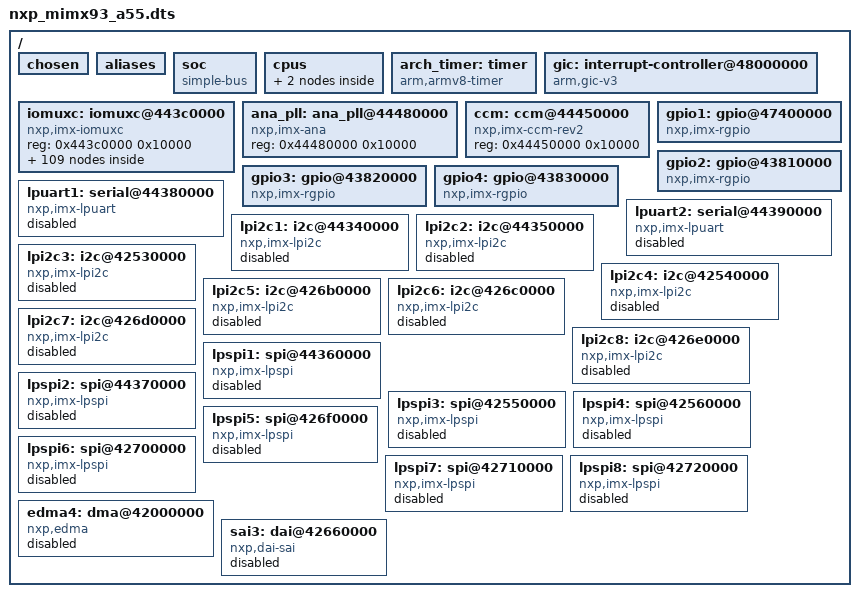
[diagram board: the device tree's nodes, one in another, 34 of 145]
/dts-v1/;

/ {
	#address-cells = < 0x1 >;
	#size-cells = < 0x1 >;
	chosen {
	};
	aliases {
	};
	soc {
		#address-cells = < 0x1 >;
		#size-cells = < 0x1 >;
		compatible = "simple-bus";
		ranges;
	};
	cpus {
		#address-cells = < 0x1 >;
		#size-cells = < 0x0 >;
		cpu@0 {
			device_type = "cpu";
			compatible = "arm,cortex-a55";
			reg = < 0x0 >;
		};
		cpu@100 {
			device_type = "cpu";
			compatible = "arm,cortex-a55";
			reg = < 0x100 >;
		};
	};
	arch_timer: timer {
		compatible = "arm,armv8-timer";
		interrupts = < 0x1 0xd 0x2 0xa0 >, < 0x1 0xe 0x2 0xa0 >, < 0x1 0xb 0x2 0xa0 >, < 0x1 0xa 0x2 0xa0 >;
		interrupt-parent = < &gic >;
	};
	gic: interrupt-controller@48000000 {
		compatible = "arm,gic-v3", "arm,gic";
		reg = < 0x48000000 0x10000 >, < 0x48040000 0xc0000 >;
		interrupt-controller;
		#interrupt-cells = < 0x4 >;
		status = "okay";
		phandle = < 0x1 >;
	};
	iomuxc: iomuxc@443c0000 {
		compatible = "nxp,imx-iomuxc";
		reg = < 0x443c0000 0x10000 >;
		status = "okay";
		pinctrl: pinctrl {
			status = "okay";
			compatible = "nxp,imx93-pinctrl";
		};
		iomuxc1_ccm_clko1_gpio_io_gpio3_io26: IOMUXC1_CCM_CLKO1_GPIO_IO_GPIO3_IO26 {
			pinmux = < 0x443c0088 0x5 0x0 0x0 0x443c0238 >;
			phandle = < 0x4a >;
		};
		iomuxc1_ccm_clko2_gpio_io_gpio3_io27: IOMUXC1_CCM_CLKO2_GPIO_IO_GPIO3_IO27 {
			pinmux = < 0x443c008c 0x5 0x0 0x0 0x443c023c >;
			phandle = < 0x4b >;
		};
		iomuxc1_ccm_clko3_gpio_io_gpio4_io28: IOMUXC1_CCM_CLKO3_GPIO_IO_GPIO4_IO28 {
			pinmux = < 0x443c0090 0x5 0x0 0x0 0x443c0240 >;
			phandle = < 0x6c >;
		};
		iomuxc1_ccm_clko4_gpio_io_gpio4_io29: IOMUXC1_CCM_CLKO4_GPIO_IO_GPIO4_IO29 {
			pinmux = < 0x443c0094 0x5 0x0 0x0 0x443c0244 >;
			phandle = < 0x6d >;
		};
		iomuxc1_dap_tclk_swclk_gpio_io_gpio3_io30: IOMUXC1_DAP_TCLK_SWCLK_GPIO_IO_GPIO3_IO30 {
			pinmux = < 0x443c0008 0x5 0x0 0x0 0x443c01b8 >;
			phandle = < 0x4e >;
		};
		iomuxc1_dap_tdi_gpio_io_gpio3_io28: IOMUXC1_DAP_TDI_GPIO_IO_GPIO3_IO28 {
			pinmux = < 0x443c0000 0x5 0x0 0x0 0x443c01b0 >;
			phandle = < 0x4c >;
		};
		iomuxc1_dap_tdo_traceswo_gpio_io_gpio3_io31: IOMUXC1_DAP_TDO_TRACESWO_GPIO_IO_GPIO3_IO31 {
			pinmux = < 0x443c000c 0x5 0x0 0x0 0x443c01bc >;
			phandle = < 0x4f >;
		};
		iomuxc1_dap_tms_swdio_gpio_io_gpio3_io29: IOMUXC1_DAP_TMS_SWDIO_GPIO_IO_GPIO3_IO29 {
			pinmux = < 0x443c0004 0x5 0x0 0x0 0x443c01b4 >;
			phandle = < 0x4d >;
		};
		iomuxc1_enet1_mdc_gpio_io_gpio4_io00: IOMUXC1_ENET1_MDC_GPIO_IO_GPIO4_IO00 {
			pinmux = < 0x443c0098 0x5 0x0 0x0 0x443c0248 >;
			phandle = < 0x50 >;
		};
		iomuxc1_enet1_mdio_gpio_io_gpio4_io01: IOMUXC1_ENET1_MDIO_GPIO_IO_GPIO4_IO01 {
			pinmux = < 0x443c009c 0x5 0x0 0x0 0x443c024c >;
			phandle = < 0x51 >;
		};
		iomuxc1_enet1_rd0_gpio_io_gpio4_io10: IOMUXC1_ENET1_RD0_GPIO_IO_GPIO4_IO10 {
			pinmux = < 0x443c00c0 0x5 0x0 0x0 0x443c0270 >;
			phandle = < 0x5a >;
		};
		iomuxc1_enet1_rd1_gpio_io_gpio4_io11: IOMUXC1_ENET1_RD1_GPIO_IO_GPIO4_IO11 {
			pinmux = < 0x443c00c4 0x5 0x0 0x0 0x443c0274 >;
			phandle = < 0x5b >;
		};
		iomuxc1_enet1_rd2_gpio_io_gpio4_io12: IOMUXC1_ENET1_RD2_GPIO_IO_GPIO4_IO12 {
			pinmux = < 0x443c00c8 0x5 0x0 0x0 0x443c0278 >;
			phandle = < 0x5c >;
		};
		iomuxc1_enet1_rd3_gpio_io_gpio4_io13: IOMUXC1_ENET1_RD3_GPIO_IO_GPIO4_IO13 {
			pinmux = < 0x443c00cc 0x5 0x0 0x0 0x443c027c >;
			phandle = < 0x5d >;
		};
		iomuxc1_enet1_rxc_gpio_io_gpio4_io09: IOMUXC1_ENET1_RXC_GPIO_IO_GPIO4_IO09 {
			pinmux = < 0x443c00bc 0x5 0x0 0x0 0x443c026c >;
			phandle = < 0x59 >;
		};
		iomuxc1_enet1_rx_ctl_gpio_io_gpio4_io08: IOMUXC1_ENET1_RX_CTL_GPIO_IO_GPIO4_IO08 {
			pinmux = < 0x443c00b8 0x5 0x0 0x0 0x443c0268 >;
			phandle = < 0x58 >;
		};
		iomuxc1_enet1_td0_gpio_io_gpio4_io05: IOMUXC1_ENET1_TD0_GPIO_IO_GPIO4_IO05 {
			pinmux = < 0x443c00ac 0x5 0x0 0x0 0x443c025c >;
			phandle = < 0x55 >;
		};
		iomuxc1_enet1_td1_gpio_io_gpio4_io04: IOMUXC1_ENET1_TD1_GPIO_IO_GPIO4_IO04 {
			pinmux = < 0x443c00a8 0x5 0x0 0x0 0x443c0258 >;
			phandle = < 0x54 >;
		};
		iomuxc1_enet1_td2_gpio_io_gpio4_io03: IOMUXC1_ENET1_TD2_GPIO_IO_GPIO4_IO03 {
			pinmux = < 0x443c00a4 0x5 0x0 0x0 0x443c0254 >;
			phandle = < 0x53 >;
		};
		iomuxc1_enet1_td3_gpio_io_gpio4_io02: IOMUXC1_ENET1_TD3_GPIO_IO_GPIO4_IO02 {
			pinmux = < 0x443c00a0 0x5 0x0 0x0 0x443c0250 >;
			phandle = < 0x52 >;
		};
		iomuxc1_enet1_txc_gpio_io_gpio4_io07: IOMUXC1_ENET1_TXC_GPIO_IO_GPIO4_IO07 {
			pinmux = < 0x443c00b4 0x5 0x0 0x0 0x443c0264 >;
			phandle = < 0x57 >;
		};
		iomuxc1_enet1_tx_ctl_gpio_io_gpio4_io06: IOMUXC1_ENET1_TX_CTL_GPIO_IO_GPIO4_IO06 {
			pinmux = < 0x443c00b0 0x5 0x0 0x0 0x443c0260 >;
			phandle = < 0x56 >;
		};
		iomuxc1_enet2_mdc_gpio_io_gpio4_io14: IOMUXC1_ENET2_MDC_GPIO_IO_GPIO4_IO14 {
			pinmux = < 0x443c00d0 0x5 0x0 0x0 0x443c0280 >;
			phandle = < 0x5e >;
		};
		iomuxc1_enet2_mdio_gpio_io_gpio4_io15: IOMUXC1_ENET2_MDIO_GPIO_IO_GPIO4_IO15 {
			pinmux = < 0x443c00d4 0x5 0x0 0x0 0x443c0284 >;
			phandle = < 0x5f >;
		};
		iomuxc1_enet2_rd0_gpio_io_gpio4_io24: IOMUXC1_ENET2_RD0_GPIO_IO_GPIO4_IO24 {
			pinmux = < 0x443c00f8 0x5 0x0 0x0 0x443c02a8 >;
			phandle = < 0x68 >;
		};
		iomuxc1_enet2_rd1_gpio_io_gpio4_io25: IOMUXC1_ENET2_RD1_GPIO_IO_GPIO4_IO25 {
			pinmux = < 0x443c00fc 0x5 0x0 0x0 0x443c02ac >;
			phandle = < 0x69 >;
		};
		iomuxc1_enet2_rd2_gpio_io_gpio4_io26: IOMUXC1_ENET2_RD2_GPIO_IO_GPIO4_IO26 {
			pinmux = < 0x443c0100 0x5 0x0 0x0 0x443c02b0 >;
			phandle = < 0x6a >;
		};
		iomuxc1_enet2_rd3_gpio_io_gpio4_io27: IOMUXC1_ENET2_RD3_GPIO_IO_GPIO4_IO27 {
			pinmux = < 0x443c0104 0x5 0x0 0x0 0x443c02b4 >;
			phandle = < 0x6b >;
		};
		iomuxc1_enet2_rxc_gpio_io_gpio4_io23: IOMUXC1_ENET2_RXC_GPIO_IO_GPIO4_IO23 {
			pinmux = < 0x443c00f4 0x5 0x0 0x0 0x443c02a4 >;
			phandle = < 0x67 >;
		};
		iomuxc1_enet2_rx_ctl_gpio_io_gpio4_io22: IOMUXC1_ENET2_RX_CTL_GPIO_IO_GPIO4_IO22 {
			pinmux = < 0x443c00f0 0x5 0x0 0x0 0x443c02a0 >;
			phandle = < 0x66 >;
		};
		iomuxc1_enet2_td0_gpio_io_gpio4_io19: IOMUXC1_ENET2_TD0_GPIO_IO_GPIO4_IO19 {
			pinmux = < 0x443c00e4 0x5 0x0 0x0 0x443c0294 >;
			phandle = < 0x63 >;
		};
		iomuxc1_enet2_td1_gpio_io_gpio4_io18: IOMUXC1_ENET2_TD1_GPIO_IO_GPIO4_IO18 {
			pinmux = < 0x443c00e0 0x5 0x0 0x0 0x443c0290 >;
			phandle = < 0x62 >;
		};
		iomuxc1_enet2_td2_gpio_io_gpio4_io17: IOMUXC1_ENET2_TD2_GPIO_IO_GPIO4_IO17 {
			pinmux = < 0x443c00dc 0x5 0x0 0x0 0x443c028c >;
			phandle = < 0x61 >;
		};
		iomuxc1_enet2_td3_gpio_io_gpio4_io16: IOMUXC1_ENET2_TD3_GPIO_IO_GPIO4_IO16 {
			pinmux = < 0x443c00d8 0x5 0x0 0x0 0x443c0288 >;
			phandle = < 0x60 >;
		};
		iomuxc1_enet2_txc_gpio_io_gpio4_io21: IOMUXC1_ENET2_TXC_GPIO_IO_GPIO4_IO21 {
			pinmux = < 0x443c00ec 0x5 0x0 0x0 0x443c029c >;
			phandle = < 0x65 >;
		};
		iomuxc1_enet2_tx_ctl_gpio_io_gpio4_io20: IOMUXC1_ENET2_TX_CTL_GPIO_IO_GPIO4_IO20 {
			pinmux = < 0x443c00e8 0x5 0x0 0x0 0x443c0298 >;
			phandle = < 0x64 >;
		};
		iomuxc1_gpio_io00_gpio_io_gpio2_io00: IOMUXC1_GPIO_IO00_GPIO_IO_GPIO2_IO00 {
			pinmux = < 0x443c0010 0x0 0x0 0x0 0x443c01c0 >;
			phandle = < 0x12 >;
		};
		iomuxc1_gpio_io01_gpio_io_gpio2_io01: IOMUXC1_GPIO_IO01_GPIO_IO_GPIO2_IO01 {
			pinmux = < 0x443c0014 0x0 0x0 0x0 0x443c01c4 >;
			phandle = < 0x13 >;
		};
		iomuxc1_gpio_io02_gpio_io_gpio2_io02: IOMUXC1_GPIO_IO02_GPIO_IO_GPIO2_IO02 {
			pinmux = < 0x443c0018 0x0 0x0 0x0 0x443c01c8 >;
			phandle = < 0x14 >;
		};
		iomuxc1_gpio_io03_gpio_io_gpio2_io03: IOMUXC1_GPIO_IO03_GPIO_IO_GPIO2_IO03 {
			pinmux = < 0x443c001c 0x0 0x0 0x0 0x443c01cc >;
			phandle = < 0x15 >;
		};
		iomuxc1_gpio_io04_gpio_io_gpio2_io04: IOMUXC1_GPIO_IO04_GPIO_IO_GPIO2_IO04 {
			pinmux = < 0x443c0020 0x0 0x0 0x0 0x443c01d0 >;
			phandle = < 0x16 >;
		};
		iomuxc1_gpio_io05_gpio_io_gpio2_io05: IOMUXC1_GPIO_IO05_GPIO_IO_GPIO2_IO05 {
			pinmux = < 0x443c0024 0x0 0x0 0x0 0x443c01d4 >;
			phandle = < 0x17 >;
		};
		iomuxc1_gpio_io06_gpio_io_gpio2_io06: IOMUXC1_GPIO_IO06_GPIO_IO_GPIO2_IO06 {
			pinmux = < 0x443c0028 0x0 0x0 0x0 0x443c01d8 >;
			phandle = < 0x18 >;
		};
		iomuxc1_gpio_io07_gpio_io_gpio2_io07: IOMUXC1_GPIO_IO07_GPIO_IO_GPIO2_IO07 {
			pinmux = < 0x443c002c 0x0 0x0 0x0 0x443c01dc >;
			phandle = < 0x19 >;
		};
		iomuxc1_gpio_io08_gpio_io_gpio2_io08: IOMUXC1_GPIO_IO08_GPIO_IO_GPIO2_IO08 {
			pinmux = < 0x443c0030 0x0 0x0 0x0 0x443c01e0 >;
			phandle = < 0x1a >;
		};
		iomuxc1_gpio_io09_gpio_io_gpio2_io09: IOMUXC1_GPIO_IO09_GPIO_IO_GPIO2_IO09 {
			pinmux = < 0x443c0034 0x0 0x0 0x0 0x443c01e4 >;
			phandle = < 0x1b >;
		};
		iomuxc1_gpio_io10_gpio_io_gpio2_io10: IOMUXC1_GPIO_IO10_GPIO_IO_GPIO2_IO10 {
			pinmux = < 0x443c0038 0x0 0x0 0x0 0x443c01e8 >;
			phandle = < 0x1c >;
		};
		iomuxc1_gpio_io11_gpio_io_gpio2_io11: IOMUXC1_GPIO_IO11_GPIO_IO_GPIO2_IO11 {
			pinmux = < 0x443c003c 0x0 0x0 0x0 0x443c01ec >;
			phandle = < 0x1d >;
		};
		iomuxc1_gpio_io12_gpio_io_gpio2_io12: IOMUXC1_GPIO_IO12_GPIO_IO_GPIO2_IO12 {
			pinmux = < 0x443c0040 0x0 0x0 0x0 0x443c01f0 >;
			phandle = < 0x1e >;
		};
		iomuxc1_gpio_io13_gpio_io_gpio2_io13: IOMUXC1_GPIO_IO13_GPIO_IO_GPIO2_IO13 {
			pinmux = < 0x443c0044 0x0 0x0 0x0 0x443c01f4 >;
			phandle = < 0x1f >;
		};
		iomuxc1_gpio_io14_gpio_io_gpio2_io14: IOMUXC1_GPIO_IO14_GPIO_IO_GPIO2_IO14 {
			pinmux = < 0x443c0048 0x0 0x0 0x0 0x443c01f8 >;
			phandle = < 0x20 >;
		};
		iomuxc1_gpio_io15_gpio_io_gpio2_io15: IOMUXC1_GPIO_IO15_GPIO_IO_GPIO2_IO15 {
			pinmux = < 0x443c004c 0x0 0x0 0x0 0x443c01fc >;
			phandle = < 0x21 >;
		};
		iomuxc1_gpio_io16_gpio_io_gpio2_io16: IOMUXC1_GPIO_IO16_GPIO_IO_GPIO2_IO16 {
			pinmux = < 0x443c0050 0x0 0x0 0x0 0x443c0200 >;
			phandle = < 0x22 >;
		};
		iomuxc1_gpio_io17_gpio_io_gpio2_io17: IOMUXC1_GPIO_IO17_GPIO_IO_GPIO2_IO17 {
			pinmux = < 0x443c0054 0x0 0x0 0x0 0x443c0204 >;
			phandle = < 0x23 >;
		};
		iomuxc1_gpio_io18_gpio_io_gpio2_io18: IOMUXC1_GPIO_IO18_GPIO_IO_GPIO2_IO18 {
			pinmux = < 0x443c0058 0x0 0x0 0x0 0x443c0208 >;
			phandle = < 0x24 >;
		};
		iomuxc1_gpio_io19_gpio_io_gpio2_io19: IOMUXC1_GPIO_IO19_GPIO_IO_GPIO2_IO19 {
			pinmux = < 0x443c005c 0x0 0x0 0x0 0x443c020c >;
			phandle = < 0x25 >;
		};
		iomuxc1_gpio_io20_gpio_io_gpio2_io20: IOMUXC1_GPIO_IO20_GPIO_IO_GPIO2_IO20 {
			pinmux = < 0x443c0060 0x0 0x0 0x0 0x443c0210 >;
			phandle = < 0x26 >;
		};
		iomuxc1_gpio_io21_gpio_io_gpio2_io21: IOMUXC1_GPIO_IO21_GPIO_IO_GPIO2_IO21 {
			pinmux = < 0x443c0064 0x0 0x0 0x0 0x443c0214 >;
			phandle = < 0x27 >;
		};
		iomuxc1_gpio_io22_gpio_io_gpio2_io22: IOMUXC1_GPIO_IO22_GPIO_IO_GPIO2_IO22 {
			pinmux = < 0x443c0068 0x0 0x0 0x0 0x443c0218 >;
			phandle = < 0x28 >;
		};
		iomuxc1_gpio_io23_gpio_io_gpio2_io23: IOMUXC1_GPIO_IO23_GPIO_IO_GPIO2_IO23 {
			pinmux = < 0x443c006c 0x0 0x0 0x0 0x443c021c >;
			phandle = < 0x29 >;
		};
		iomuxc1_gpio_io24_gpio_io_gpio2_io24: IOMUXC1_GPIO_IO24_GPIO_IO_GPIO2_IO24 {
			pinmux = < 0x443c0070 0x0 0x0 0x0 0x443c0220 >;
			phandle = < 0x2a >;
		};
		iomuxc1_gpio_io25_gpio_io_gpio2_io25: IOMUXC1_GPIO_IO25_GPIO_IO_GPIO2_IO25 {
			pinmux = < 0x443c0074 0x0 0x0 0x0 0x443c0224 >;
			phandle = < 0x2b >;
		};
		iomuxc1_gpio_io26_gpio_io_gpio2_io26: IOMUXC1_GPIO_IO26_GPIO_IO_GPIO2_IO26 {
			pinmux = < 0x443c0078 0x0 0x0 0x0 0x443c0228 >;
			phandle = < 0x2c >;
		};
		iomuxc1_gpio_io27_gpio_io_gpio2_io27: IOMUXC1_GPIO_IO27_GPIO_IO_GPIO2_IO27 {
			pinmux = < 0x443c007c 0x0 0x0 0x0 0x443c022c >;
			phandle = < 0x2d >;
		};
		iomuxc1_gpio_io28_gpio_io_gpio2_io28: IOMUXC1_GPIO_IO28_GPIO_IO_GPIO2_IO28 {
			pinmux = < 0x443c0080 0x0 0x0 0x0 0x443c0230 >;
			phandle = < 0x2e >;
		};
		iomuxc1_gpio_io29_gpio_io_gpio2_io29: IOMUXC1_GPIO_IO29_GPIO_IO_GPIO2_IO29 {
			pinmux = < 0x443c0084 0x0 0x0 0x0 0x443c0234 >;
			phandle = < 0x2f >;
		};
		iomuxc1_i2c1_scl_gpio_io_gpio1_io00: IOMUXC1_I2C1_SCL_GPIO_IO_GPIO1_IO00 {
			pinmux = < 0x443c0170 0x5 0x0 0x0 0x443c0320 >;
			phandle = < 0x2 >;
		};
		iomuxc1_i2c1_sda_gpio_io_gpio1_io01: IOMUXC1_I2C1_SDA_GPIO_IO_GPIO1_IO01 {
			pinmux = < 0x443c0174 0x5 0x0 0x0 0x443c0324 >;
			phandle = < 0x3 >;
		};
		iomuxc1_i2c2_scl_gpio_io_gpio1_io02: IOMUXC1_I2C2_SCL_GPIO_IO_GPIO1_IO02 {
			pinmux = < 0x443c0178 0x5 0x0 0x0 0x443c0328 >;
			phandle = < 0x4 >;
		};
		iomuxc1_i2c2_sda_gpio_io_gpio1_io03: IOMUXC1_I2C2_SDA_GPIO_IO_GPIO1_IO03 {
			pinmux = < 0x443c017c 0x5 0x0 0x0 0x443c032c >;
			phandle = < 0x5 >;
		};
		iomuxc1_pdm_bit_stream0_gpio_io_gpio1_io09: IOMUXC1_PDM_BIT_STREAM0_GPIO_IO_GPIO1_IO09 {
			pinmux = < 0x443c0194 0x5 0x0 0x0 0x443c0344 >;
			phandle = < 0xb >;
		};
		iomuxc1_pdm_bit_stream1_gpio_io_gpio1_io10: IOMUXC1_PDM_BIT_STREAM1_GPIO_IO_GPIO1_IO10 {
			pinmux = < 0x443c0198 0x5 0x0 0x0 0x443c0348 >;
			phandle = < 0xc >;
		};
		iomuxc1_pdm_clk_gpio_io_gpio1_io08: IOMUXC1_PDM_CLK_GPIO_IO_GPIO1_IO08 {
			pinmux = < 0x443c0190 0x5 0x0 0x0 0x443c0340 >;
			phandle = < 0xa >;
		};
		iomuxc1_sai1_rxd0_gpio_io_gpio1_io14: IOMUXC1_SAI1_RXD0_GPIO_IO_GPIO1_IO14 {
			pinmux = < 0x443c01a8 0x5 0x0 0x0 0x443c0358 >;
			phandle = < 0x10 >;
		};
		iomuxc1_sai1_txc_gpio_io_gpio1_io12: IOMUXC1_SAI1_TXC_GPIO_IO_GPIO1_IO12 {
			pinmux = < 0x443c01a0 0x5 0x0 0x0 0x443c0350 >;
			phandle = < 0xe >;
		};
		iomuxc1_sai1_txd0_gpio_io_gpio1_io13: IOMUXC1_SAI1_TXD0_GPIO_IO_GPIO1_IO13 {
			pinmux = < 0x443c01a4 0x5 0x0 0x0 0x443c0354 >;
			phandle = < 0xf >;
		};
		iomuxc1_sai1_txfs_gpio_io_gpio1_io11: IOMUXC1_SAI1_TXFS_GPIO_IO_GPIO1_IO11 {
			pinmux = < 0x443c019c 0x5 0x0 0x0 0x443c034c >;
			phandle = < 0xd >;
		};
		iomuxc1_sd1_clk_gpio_io_gpio3_io08: IOMUXC1_SD1_CLK_GPIO_IO_GPIO3_IO08 {
			pinmux = < 0x443c0108 0x5 0x0 0x0 0x443c02b8 >;
			phandle = < 0x38 >;
		};
		iomuxc1_sd1_cmd_gpio_io_gpio3_io09: IOMUXC1_SD1_CMD_GPIO_IO_GPIO3_IO09 {
			pinmux = < 0x443c010c 0x5 0x0 0x0 0x443c02bc >;
			phandle = < 0x39 >;
		};
		iomuxc1_sd1_data0_gpio_io_gpio3_io10: IOMUXC1_SD1_DATA0_GPIO_IO_GPIO3_IO10 {
			pinmux = < 0x443c0110 0x5 0x0 0x0 0x443c02c0 >;
			phandle = < 0x3a >;
		};
		iomuxc1_sd1_data1_gpio_io_gpio3_io11: IOMUXC1_SD1_DATA1_GPIO_IO_GPIO3_IO11 {
			pinmux = < 0x443c0114 0x5 0x0 0x0 0x443c02c4 >;
			phandle = < 0x3b >;
		};
		iomuxc1_sd1_data2_gpio_io_gpio3_io12: IOMUXC1_SD1_DATA2_GPIO_IO_GPIO3_IO12 {
			pinmux = < 0x443c0118 0x5 0x0 0x0 0x443c02c8 >;
			phandle = < 0x3c >;
		};
		iomuxc1_sd1_data3_gpio_io_gpio3_io13: IOMUXC1_SD1_DATA3_GPIO_IO_GPIO3_IO13 {
			pinmux = < 0x443c011c 0x5 0x0 0x0 0x443c02cc >;
			phandle = < 0x3d >;
		};
		iomuxc1_sd1_data4_gpio_io_gpio3_io14: IOMUXC1_SD1_DATA4_GPIO_IO_GPIO3_IO14 {
			pinmux = < 0x443c0120 0x5 0x0 0x0 0x443c02d0 >;
			phandle = < 0x3e >;
		};
		iomuxc1_sd1_data5_gpio_io_gpio3_io15: IOMUXC1_SD1_DATA5_GPIO_IO_GPIO3_IO15 {
			pinmux = < 0x443c0124 0x5 0x0 0x0 0x443c02d4 >;
			phandle = < 0x3f >;
		};
		iomuxc1_sd1_data6_gpio_io_gpio3_io16: IOMUXC1_SD1_DATA6_GPIO_IO_GPIO3_IO16 {
			pinmux = < 0x443c0128 0x5 0x0 0x0 0x443c02d8 >;
			phandle = < 0x40 >;
		};
		iomuxc1_sd1_data7_gpio_io_gpio3_io17: IOMUXC1_SD1_DATA7_GPIO_IO_GPIO3_IO17 {
			pinmux = < 0x443c012c 0x5 0x0 0x0 0x443c02dc >;
			phandle = < 0x41 >;
		};
		iomuxc1_sd1_strobe_gpio_io_gpio3_io18: IOMUXC1_SD1_STROBE_GPIO_IO_GPIO3_IO18 {
			pinmux = < 0x443c0130 0x5 0x0 0x0 0x443c02e0 >;
			phandle = < 0x42 >;
		};
		iomuxc1_sd2_cd_b_gpio_io_gpio3_io00: IOMUXC1_SD2_CD_B_GPIO_IO_GPIO3_IO00 {
			pinmux = < 0x443c0150 0x5 0x0 0x0 0x443c0300 >;
			phandle = < 0x30 >;
		};
		iomuxc1_sd2_clk_gpio_io_gpio3_io01: IOMUXC1_SD2_CLK_GPIO_IO_GPIO3_IO01 {
			pinmux = < 0x443c0154 0x5 0x0 0x0 0x443c0304 >;
			phandle = < 0x31 >;
		};
		iomuxc1_sd2_cmd_gpio_io_gpio3_io02: IOMUXC1_SD2_CMD_GPIO_IO_GPIO3_IO02 {
			pinmux = < 0x443c0158 0x5 0x0 0x0 0x443c0308 >;
			phandle = < 0x32 >;
		};
		iomuxc1_sd2_data0_gpio_io_gpio3_io03: IOMUXC1_SD2_DATA0_GPIO_IO_GPIO3_IO03 {
			pinmux = < 0x443c015c 0x5 0x0 0x0 0x443c030c >;
			phandle = < 0x33 >;
		};
		iomuxc1_sd2_data1_gpio_io_gpio3_io04: IOMUXC1_SD2_DATA1_GPIO_IO_GPIO3_IO04 {
			pinmux = < 0x443c0160 0x5 0x0 0x0 0x443c0310 >;
			phandle = < 0x34 >;
		};
		iomuxc1_sd2_data2_gpio_io_gpio3_io05: IOMUXC1_SD2_DATA2_GPIO_IO_GPIO3_IO05 {
			pinmux = < 0x443c0164 0x5 0x0 0x0 0x443c0314 >;
			phandle = < 0x35 >;
		};
		iomuxc1_sd2_data3_gpio_io_gpio3_io06: IOMUXC1_SD2_DATA3_GPIO_IO_GPIO3_IO06 {
			pinmux = < 0x443c0168 0x5 0x0 0x0 0x443c0318 >;
			phandle = < 0x36 >;
		};
		iomuxc1_sd2_reset_b_gpio_io_gpio3_io07: IOMUXC1_SD2_RESET_B_GPIO_IO_GPIO3_IO07 {
			pinmux = < 0x443c016c 0x5 0x0 0x0 0x443c031c >;
			phandle = < 0x37 >;
		};
		iomuxc1_sd2_vselect_gpio_io_gpio3_io19: IOMUXC1_SD2_VSELECT_GPIO_IO_GPIO3_IO19 {
			pinmux = < 0x443c0134 0x5 0x0 0x0 0x443c02e4 >;
			phandle = < 0x43 >;
		};
		iomuxc1_sd3_clk_gpio_io_gpio3_io20: IOMUXC1_SD3_CLK_GPIO_IO_GPIO3_IO20 {
			pinmux = < 0x443c0138 0x5 0x0 0x0 0x443c02e8 >;
			phandle = < 0x44 >;
		};
		iomuxc1_sd3_cmd_gpio_io_gpio3_io21: IOMUXC1_SD3_CMD_GPIO_IO_GPIO3_IO21 {
			pinmux = < 0x443c013c 0x5 0x0 0x0 0x443c02ec >;
			phandle = < 0x45 >;
		};
		iomuxc1_sd3_data0_gpio_io_gpio3_io22: IOMUXC1_SD3_DATA0_GPIO_IO_GPIO3_IO22 {
			pinmux = < 0x443c0140 0x5 0x0 0x0 0x443c02f0 >;
			phandle = < 0x46 >;
		};
		iomuxc1_sd3_data1_gpio_io_gpio3_io23: IOMUXC1_SD3_DATA1_GPIO_IO_GPIO3_IO23 {
			pinmux = < 0x443c0144 0x5 0x0 0x0 0x443c02f4 >;
			phandle = < 0x47 >;
		};
		iomuxc1_sd3_data2_gpio_io_gpio3_io24: IOMUXC1_SD3_DATA2_GPIO_IO_GPIO3_IO24 {
			pinmux = < 0x443c0148 0x5 0x0 0x0 0x443c02f8 >;
			phandle = < 0x48 >;
		};
		iomuxc1_sd3_data3_gpio_io_gpio3_io25: IOMUXC1_SD3_DATA3_GPIO_IO_GPIO3_IO25 {
			pinmux = < 0x443c014c 0x5 0x0 0x0 0x443c02fc >;
			phandle = < 0x49 >;
		};
		iomuxc1_uart1_rxd_gpio_io_gpio1_io04: IOMUXC1_UART1_RXD_GPIO_IO_GPIO1_IO04 {
			pinmux = < 0x443c0180 0x5 0x0 0x0 0x443c0330 >;
			phandle = < 0x6 >;
		};
		iomuxc1_uart1_txd_gpio_io_gpio1_io05: IOMUXC1_UART1_TXD_GPIO_IO_GPIO1_IO05 {
			pinmux = < 0x443c0184 0x5 0x0 0x0 0x443c0334 >;
			phandle = < 0x7 >;
		};
		iomuxc1_uart2_rxd_gpio_io_gpio1_io06: IOMUXC1_UART2_RXD_GPIO_IO_GPIO1_IO06 {
			pinmux = < 0x443c0188 0x5 0x0 0x0 0x443c0338 >;
			phandle = < 0x8 >;
		};
		iomuxc1_uart2_txd_gpio_io_gpio1_io07: IOMUXC1_UART2_TXD_GPIO_IO_GPIO1_IO07 {
			pinmux = < 0x443c018c 0x5 0x0 0x0 0x443c033c >;
			phandle = < 0x9 >;
		};
		iomuxc1_wdog_any_gpio_io_gpio1_io15: IOMUXC1_WDOG_ANY_GPIO_IO_GPIO1_IO15 {
			pinmux = < 0x443c01ac 0x5 0x0 0x0 0x443c035c >;
			phandle = < 0x11 >;
		};
	};
	ana_pll: ana_pll@44480000 {
		compatible = "nxp,imx-ana";
		reg = < 0x44480000 0x10000 >;
	};
	ccm: ccm@44450000 {
		compatible = "nxp,imx-ccm-rev2";
		reg = < 0x44450000 0x10000 >;
		#clock-cells = < 0x3 >;
		phandle = < 0x6e >;
	};
	gpio1: gpio@47400000 {
		compatible = "nxp,imx-rgpio";
		reg = < 0x47400000 0x10000 >;
		interrupt-parent = < &gic >;
		interrupts = < 0x0 0xa 0x2 0xa0 >, < 0x0 0xb 0x2 0xa0 >;
		gpio-controller;
		#gpio-cells = < 0x2 >;
		pinmux = < &iomuxc1_i2c1_scl_gpio_io_gpio1_io00 >, < &iomuxc1_i2c1_sda_gpio_io_gpio1_io01 >, < &iomuxc1_i2c2_scl_gpio_io_gpio1_io02 >, < &iomuxc1_i2c2_sda_gpio_io_gpio1_io03 >, < &iomuxc1_uart1_rxd_gpio_io_gpio1_io04 >, < &iomuxc1_uart1_txd_gpio_io_gpio1_io05 >, < &iomuxc1_uart2_rxd_gpio_io_gpio1_io06 >, < &iomuxc1_uart2_txd_gpio_io_gpio1_io07 >, < &iomuxc1_pdm_clk_gpio_io_gpio1_io08 >, < &iomuxc1_pdm_bit_stream0_gpio_io_gpio1_io09 >, < &iomuxc1_pdm_bit_stream1_gpio_io_gpio1_io10 >, < &iomuxc1_sai1_txfs_gpio_io_gpio1_io11 >, < &iomuxc1_sai1_txc_gpio_io_gpio1_io12 >, < &iomuxc1_sai1_txd0_gpio_io_gpio1_io13 >, < &iomuxc1_sai1_rxd0_gpio_io_gpio1_io14 >, < &iomuxc1_wdog_any_gpio_io_gpio1_io15 >;
	};
	gpio2: gpio@43810000 {
		compatible = "nxp,imx-rgpio";
		reg = < 0x43810000 0x10000 >;
		interrupt-parent = < &gic >;
		interrupts = < 0x0 0x39 0x2 0xa0 >, < 0x0 0x3a 0x2 0xa0 >;
		gpio-controller;
		#gpio-cells = < 0x2 >;
		pinmux = < &iomuxc1_gpio_io00_gpio_io_gpio2_io00 >, < &iomuxc1_gpio_io01_gpio_io_gpio2_io01 >, < &iomuxc1_gpio_io02_gpio_io_gpio2_io02 >, < &iomuxc1_gpio_io03_gpio_io_gpio2_io03 >, < &iomuxc1_gpio_io04_gpio_io_gpio2_io04 >, < &iomuxc1_gpio_io05_gpio_io_gpio2_io05 >, < &iomuxc1_gpio_io06_gpio_io_gpio2_io06 >, < &iomuxc1_gpio_io07_gpio_io_gpio2_io07 >, < &iomuxc1_gpio_io08_gpio_io_gpio2_io08 >, < &iomuxc1_gpio_io09_gpio_io_gpio2_io09 >, < &iomuxc1_gpio_io10_gpio_io_gpio2_io10 >, < &iomuxc1_gpio_io11_gpio_io_gpio2_io11 >, < &iomuxc1_gpio_io12_gpio_io_gpio2_io12 >, < &iomuxc1_gpio_io13_gpio_io_gpio2_io13 >, < &iomuxc1_gpio_io14_gpio_io_gpio2_io14 >, < &iomuxc1_gpio_io15_gpio_io_gpio2_io15 >, < &iomuxc1_gpio_io16_gpio_io_gpio2_io16 >, < &iomuxc1_gpio_io17_gpio_io_gpio2_io17 >, < &iomuxc1_gpio_io18_gpio_io_gpio2_io18 >, < &iomuxc1_gpio_io19_gpio_io_gpio2_io19 >, < &iomuxc1_gpio_io20_gpio_io_gpio2_io20 >, < &iomuxc1_gpio_io21_gpio_io_gpio2_io21 >, < &iomuxc1_gpio_io22_gpio_io_gpio2_io22 >, < &iomuxc1_gpio_io23_gpio_io_gpio2_io23 >, < &iomuxc1_gpio_io24_gpio_io_gpio2_io24 >, < &iomuxc1_gpio_io25_gpio_io_gpio2_io25 >, < &iomuxc1_gpio_io26_gpio_io_gpio2_io26 >, < &iomuxc1_gpio_io27_gpio_io_gpio2_io27 >, < &iomuxc1_gpio_io28_gpio_io_gpio2_io28 >, < &iomuxc1_gpio_io29_gpio_io_gpio2_io29 >;
	};
	gpio3: gpio@43820000 {
		compatible = "nxp,imx-rgpio";
		reg = < 0x43820000 0x10000 >;
		interrupt-parent = < &gic >;
		interrupts = < 0x0 0x3b 0x2 0xa0 >, < 0x0 0x3c 0x2 0xa0 >;
		gpio-controller;
		#gpio-cells = < 0x2 >;
		pinmux = < &iomuxc1_sd2_cd_b_gpio_io_gpio3_io00 >, < &iomuxc1_sd2_clk_gpio_io_gpio3_io01 >, < &iomuxc1_sd2_cmd_gpio_io_gpio3_io02 >, < &iomuxc1_sd2_data0_gpio_io_gpio3_io03 >, < &iomuxc1_sd2_data1_gpio_io_gpio3_io04 >, < &iomuxc1_sd2_data2_gpio_io_gpio3_io05 >, < &iomuxc1_sd2_data3_gpio_io_gpio3_io06 >, < &iomuxc1_sd2_reset_b_gpio_io_gpio3_io07 >, < &iomuxc1_sd1_clk_gpio_io_gpio3_io08 >, < &iomuxc1_sd1_cmd_gpio_io_gpio3_io09 >, < &iomuxc1_sd1_data0_gpio_io_gpio3_io10 >, < &iomuxc1_sd1_data1_gpio_io_gpio3_io11 >, < &iomuxc1_sd1_data2_gpio_io_gpio3_io12 >, < &iomuxc1_sd1_data3_gpio_io_gpio3_io13 >, < &iomuxc1_sd1_data4_gpio_io_gpio3_io14 >, < &iomuxc1_sd1_data5_gpio_io_gpio3_io15 >, < &iomuxc1_sd1_data6_gpio_io_gpio3_io16 >, < &iomuxc1_sd1_data7_gpio_io_gpio3_io17 >, < &iomuxc1_sd1_strobe_gpio_io_gpio3_io18 >, < &iomuxc1_sd2_vselect_gpio_io_gpio3_io19 >, < &iomuxc1_sd3_clk_gpio_io_gpio3_io20 >, < &iomuxc1_sd3_cmd_gpio_io_gpio3_io21 >, < &iomuxc1_sd3_data0_gpio_io_gpio3_io22 >, < &iomuxc1_sd3_data1_gpio_io_gpio3_io23 >, < &iomuxc1_sd3_data2_gpio_io_gpio3_io24 >, < &iomuxc1_sd3_data3_gpio_io_gpio3_io25 >, < &iomuxc1_ccm_clko1_gpio_io_gpio3_io26 >, < &iomuxc1_ccm_clko2_gpio_io_gpio3_io27 >, < &iomuxc1_dap_tdi_gpio_io_gpio3_io28 >, < &iomuxc1_dap_tms_swdio_gpio_io_gpio3_io29 >, < &iomuxc1_dap_tclk_swclk_gpio_io_gpio3_io30 >, < &iomuxc1_dap_tdo_traceswo_gpio_io_gpio3_io31 >;
	};
	gpio4: gpio@43830000 {
		compatible = "nxp,imx-rgpio";
		reg = < 0x43830000 0x10000 >;
		interrupt-parent = < &gic >;
		interrupts = < 0x0 0xbd 0x2 0xa0 >, < 0x0 0xbe 0x2 0xa0 >;
		gpio-controller;
		#gpio-cells = < 0x2 >;
		pinmux = < &iomuxc1_enet1_mdc_gpio_io_gpio4_io00 >, < &iomuxc1_enet1_mdio_gpio_io_gpio4_io01 >, < &iomuxc1_enet1_td3_gpio_io_gpio4_io02 >, < &iomuxc1_enet1_td2_gpio_io_gpio4_io03 >, < &iomuxc1_enet1_td1_gpio_io_gpio4_io04 >, < &iomuxc1_enet1_td0_gpio_io_gpio4_io05 >, < &iomuxc1_enet1_tx_ctl_gpio_io_gpio4_io06 >, < &iomuxc1_enet1_txc_gpio_io_gpio4_io07 >, < &iomuxc1_enet1_rx_ctl_gpio_io_gpio4_io08 >, < &iomuxc1_enet1_rxc_gpio_io_gpio4_io09 >, < &iomuxc1_enet1_rd0_gpio_io_gpio4_io10 >, < &iomuxc1_enet1_rd1_gpio_io_gpio4_io11 >, < &iomuxc1_enet1_rd2_gpio_io_gpio4_io12 >, < &iomuxc1_enet1_rd3_gpio_io_gpio4_io13 >, < &iomuxc1_enet2_mdc_gpio_io_gpio4_io14 >, < &iomuxc1_enet2_mdio_gpio_io_gpio4_io15 >, < &iomuxc1_enet2_td3_gpio_io_gpio4_io16 >, < &iomuxc1_enet2_td2_gpio_io_gpio4_io17 >, < &iomuxc1_enet2_td1_gpio_io_gpio4_io18 >, < &iomuxc1_enet2_td0_gpio_io_gpio4_io19 >, < &iomuxc1_enet2_tx_ctl_gpio_io_gpio4_io20 >, < &iomuxc1_enet2_txc_gpio_io_gpio4_io21 >, < &iomuxc1_enet2_rx_ctl_gpio_io_gpio4_io22 >, < &iomuxc1_enet2_rxc_gpio_io_gpio4_io23 >, < &iomuxc1_enet2_rd0_gpio_io_gpio4_io24 >, < &iomuxc1_enet2_rd1_gpio_io_gpio4_io25 >, < &iomuxc1_enet2_rd2_gpio_io_gpio4_io26 >, < &iomuxc1_enet2_rd3_gpio_io_gpio4_io27 >, < &iomuxc1_ccm_clko3_gpio_io_gpio4_io28 >, < &iomuxc1_ccm_clko4_gpio_io_gpio4_io29 >;
	};
	lpuart1: serial@44380000 {
		compatible = "nxp,imx-lpuart", "nxp,kinetis-lpuart";
		reg = < 0x44380000 0x10000 >;
		interrupts = < 0x0 0x13 0x2 0xa0 >;
		interrupt-names = "irq_0";
		interrupt-parent = < &gic >;
		clocks = < &ccm 0x300 0x6c 0x18 >;
		status = "disabled";
	};
	lpuart2: serial@44390000 {
		compatible = "nxp,imx-lpuart", "nxp,kinetis-lpuart";
		reg = < 0x44390000 0x10000 >;
		interrupts = < 0x0 0x14 0x2 0xa0 >;
		interrupt-names = "irq_0";
		interrupt-parent = < &gic >;
		clocks = < &ccm 0x301 0x6c 0x18 >;
		status = "disabled";
	};
	lpi2c1: i2c@44340000 {
		compatible = "nxp,imx-lpi2c";
		clock-frequency = < 0x186a0 >;
		#address-cells = < 0x1 >;
		#size-cells = < 0x0 >;
		reg = < 0x44340000 0x4000 >;
		interrupts = < 0x0 0xd 0x2 0xa0 >;
		interrupt-parent = < &gic >;
		clocks = < &ccm 0x400 0x70 0x6 >;
		status = "disabled";
	};
	lpi2c2: i2c@44350000 {
		compatible = "nxp,imx-lpi2c";
		clock-frequency = < 0x186a0 >;
		#address-cells = < 0x1 >;
		#size-cells = < 0x0 >;
		reg = < 0x44350000 0x4000 >;
		interrupts = < 0x0 0xe 0x2 0xa0 >;
		interrupt-parent = < &gic >;
		clocks = < &ccm 0x401 0x70 0x8 >;
		status = "disabled";
	};
	lpi2c3: i2c@42530000 {
		compatible = "nxp,imx-lpi2c";
		clock-frequency = < 0x186a0 >;
		#address-cells = < 0x1 >;
		#size-cells = < 0x0 >;
		reg = < 0x42530000 0x4000 >;
		interrupts = < 0x0 0x3e 0x2 0xa0 >;
		interrupt-parent = < &gic >;
		clocks = < &ccm 0x402 0x70 0xa >;
		status = "disabled";
	};
	lpi2c4: i2c@42540000 {
		compatible = "nxp,imx-lpi2c";
		clock-frequency = < 0x186a0 >;
		#address-cells = < 0x1 >;
		#size-cells = < 0x0 >;
		reg = < 0x42540000 0x4000 >;
		interrupts = < 0x0 0x3f 0x2 0xa0 >;
		interrupt-parent = < &gic >;
		clocks = < &ccm 0x403 0x80 0x18 >;
		status = "disabled";
	};
	lpi2c5: i2c@426b0000 {
		compatible = "nxp,imx-lpi2c";
		clock-frequency = < 0x186a0 >;
		#address-cells = < 0x1 >;
		#size-cells = < 0x0 >;
		reg = < 0x426b0000 0x4000 >;
		interrupts = < 0x0 0xc3 0x2 0xa0 >;
		interrupt-parent = < &gic >;
		clocks = < &ccm 0x404 0x80 0x18 >;
		status = "disabled";
	};
	lpi2c6: i2c@426c0000 {
		compatible = "nxp,imx-lpi2c";
		clock-frequency = < 0x186a0 >;
		#address-cells = < 0x1 >;
		#size-cells = < 0x0 >;
		reg = < 0x426c0000 0x4000 >;
		interrupts = < 0x0 0xc4 0x2 0xa0 >;
		interrupt-parent = < &gic >;
		clocks = < &ccm 0x405 0x80 0x18 >;
		status = "disabled";
	};
	lpi2c7: i2c@426d0000 {
		compatible = "nxp,imx-lpi2c";
		clock-frequency = < 0x186a0 >;
		#address-cells = < 0x1 >;
		#size-cells = < 0x0 >;
		reg = < 0x426d0000 0x4000 >;
		interrupts = < 0x0 0xc5 0x2 0xa0 >;
		interrupt-parent = < &gic >;
		clocks = < &ccm 0x406 0x80 0x18 >;
		status = "disabled";
	};
	lpi2c8: i2c@426e0000 {
		compatible = "nxp,imx-lpi2c";
		clock-frequency = < 0x186a0 >;
		#address-cells = < 0x1 >;
		#size-cells = < 0x0 >;
		reg = < 0x426e0000 0x4000 >;
		interrupts = < 0x0 0xc6 0x2 0xa0 >;
		interrupt-parent = < &gic >;
		clocks = < &ccm 0x407 0x80 0x18 >;
		status = "disabled";
	};
	lpspi1: spi@44360000 {
		compatible = "nxp,imx-lpspi";
		reg = < 0x44360000 0x4000 >;
		interrupts = < 0x0 0x10 0x2 0xa0 >;
		interrupt-parent = < &gic >;
		status = "disabled";
		clocks = < &ccm 0x500 0x6c 0x0 >;
		#address-cells = < 0x1 >;
		#size-cells = < 0x0 >;
	};
	lpspi2: spi@44370000 {
		compatible = "nxp,imx-lpspi";
		reg = < 0x44370000 0x4000 >;
		interrupts = < 0x0 0x11 0x2 0xa0 >;
		interrupt-parent = < &gic >;
		status = "disabled";
		clocks = < &ccm 0x501 0x6c 0x2 >;
		#address-cells = < 0x1 >;
		#size-cells = < 0x0 >;
	};
	lpspi3: spi@42550000 {
		compatible = "nxp,imx-lpspi";
		reg = < 0x42550000 0x4000 >;
		interrupts = < 0x0 0x41 0x2 0xa0 >;
		interrupt-parent = < &gic >;
		status = "disabled";
		clocks = < &ccm 0x502 0x6c 0x4 >;
		#address-cells = < 0x1 >;
		#size-cells = < 0x0 >;
	};
	lpspi4: spi@42560000 {
		compatible = "nxp,imx-lpspi";
		reg = < 0x42560000 0x4000 >;
		interrupts = < 0x0 0x42 0x2 0xa0 >;
		interrupt-parent = < &gic >;
		status = "disabled";
		clocks = < &ccm 0x503 0x6c 0x6 >;
		#address-cells = < 0x1 >;
		#size-cells = < 0x0 >;
	};
	lpspi5: spi@426f0000 {
		compatible = "nxp,imx-lpspi";
		reg = < 0x426f0000 0x4000 >;
		interrupts = < 0x0 0xbf 0x2 0xa0 >;
		interrupt-parent = < &gic >;
		status = "disabled";
		clocks = < &ccm 0x504 0x6c 0x6 >;
		#address-cells = < 0x1 >;
		#size-cells = < 0x0 >;
	};
	lpspi6: spi@42700000 {
		compatible = "nxp,imx-lpspi";
		reg = < 0x42700000 0x4000 >;
		interrupts = < 0x0 0xc0 0x2 0xa0 >;
		interrupt-parent = < &gic >;
		status = "disabled";
		clocks = < &ccm 0x505 0x6c 0x6 >;
		#address-cells = < 0x1 >;
		#size-cells = < 0x0 >;
	};
	lpspi7: spi@42710000 {
		compatible = "nxp,imx-lpspi";
		reg = < 0x42710000 0x4000 >;
		interrupts = < 0x0 0xc1 0x2 0xa0 >;
		interrupt-parent = < &gic >;
		status = "disabled";
		clocks = < &ccm 0x506 0x6c 0x0 >;
		#address-cells = < 0x1 >;
		#size-cells = < 0x0 >;
	};
	lpspi8: spi@42720000 {
		compatible = "nxp,imx-lpspi";
		reg = < 0x42720000 0x4000 >;
		interrupts = < 0x0 0xc2 0x2 0xa0 >;
		interrupt-parent = < &gic >;
		status = "disabled";
		clocks = < &ccm 0x507 0x6c 0x2 >;
		#address-cells = < 0x1 >;
		#size-cells = < 0x0 >;
	};
	edma4: dma@42000000 {
		compatible = "nxp,edma";
		reg = < 0x42000000 0x200000 >;
		valid-channels = < 0x0 >, < 0x1 >;
		interrupt-parent = < &gic >;
		interrupts = < 0x0 0x80 0x2 0xa0 >, < 0x0 0x80 0x2 0xa0 >;
		#dma-cells = < 0x2 >;
		hal-cfg-index = < 0x1 >;
		status = "disabled";
		phandle = < 0x6f >;
	};
	sai3: dai@42660000 {
		compatible = "nxp,dai-sai";
		reg = < 0x42660000 0x10000 >;
		mclk-is-output;
		clocks = < &ccm 0x2002 0x0 0x0 >;
		clock-names = "mclk1";
		interrupt-parent = < &gic >;
		interrupts = < 0x0 0xab 0x2 0xa0 >;
		dai-index = < 0x3 >;
		dmas = < &edma4 0x0 0x3c >, < &edma4 0x1 0x3d >;
		dma-names = "tx", "rx";
		status = "disabled";
	};
};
